# M367 register map
File version: 0.1
CPU: 
Registers are 32-bit, read-write, reset 0x0 unless marked. A register's access mark holds for its fields unless they carry their own. Offsets are from the block's base; [hi:lo] are bit positions; {n}, {i} and the like mark numbered series.

## PG — General Purpose Input_Output Port (PG)
Base 0x400C0600
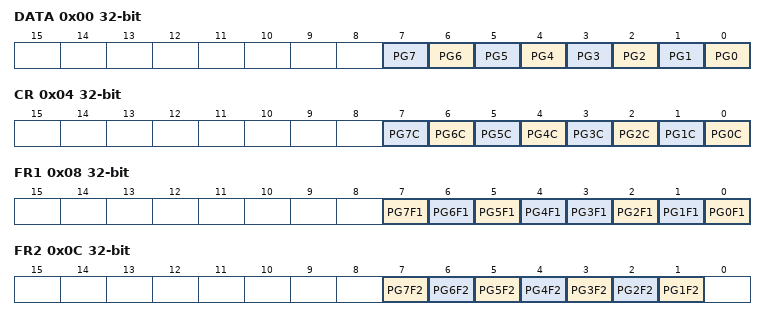
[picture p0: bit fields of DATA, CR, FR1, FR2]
0x00 DATA — PG Data Register
  [n] PG{n} (n=0..7)
0x04 CR — PG Control Register
  [n] PG{n}C (n=0..7)
0x08 FR1 — PG Function Register 1
  [7] PG7F1 ro, [6] PG6F1 ro, [5] PG5F1, [4] PG4F1 ro, [n] PG{n}F1 (n=0..3)
0x0C FR2 — PG Function Register 2
  [n] PG{n}F2 (n=1..7)
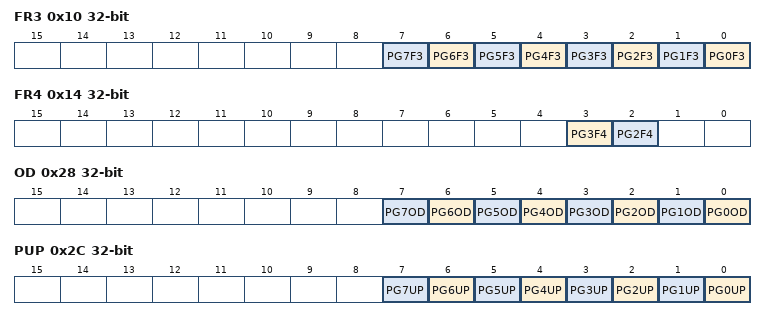
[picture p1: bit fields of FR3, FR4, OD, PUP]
0x10 FR3 — PG Function Register 3
  [n] PG{n}F3 (n=0..7)
0x14 FR4 — PG Function Register 4
  [3] PG3F4, [2] PG2F4
0x28 OD — PG Open Drain Control Register
  [n] PG{n}OD (n=0..7)
0x2C PUP — PG Pull-Up Control Register
  [n] PG{n}UP (n=0..7)
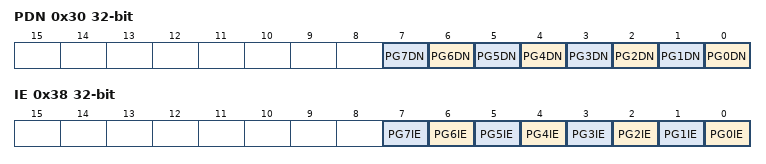
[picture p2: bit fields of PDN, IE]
0x30 PDN — PG Pull-Down Control Register
  [n] PG{n}DN (n=0..7)
0x38 IE — PG Input Enable Control Register
  [n] PG{n}IE (n=0..7)

## PH — General Purpose Input_Output Port (PH)
Base 0x400C0700
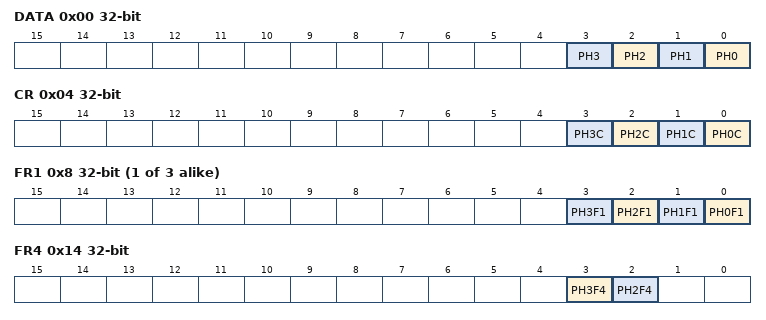
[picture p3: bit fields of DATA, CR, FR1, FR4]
0x00 DATA — PH Data Register
  [n] PH{n} (n=0..3)
0x04 CR — PH Control Register
  [n] PH{n}C (n=0..3)
{0x4+4i} FR{i} (i=1..3) — PH Function Register {i}
  [n] PH{n}F{i} (n=0..3)
0x14 FR4 — PH Function Register 4
  [3] PH3F4, [2] PH2F4
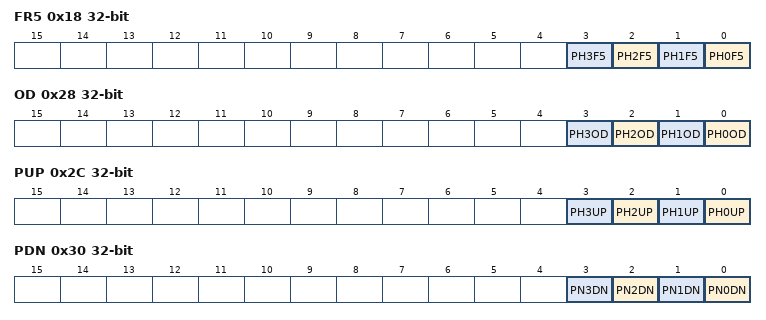
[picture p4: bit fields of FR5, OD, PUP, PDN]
0x18 FR5 — PH Function Register 5
  [n] PH{n}F5 (n=0..3)
0x28 OD — PH Open Drain Control Register
  [n] PH{n}OD (n=0..3)
0x2C PUP — PH Pull-Up Control Register
  [n] PH{n}UP (n=0..3)
0x30 PDN — PH Pull-Down Control Register
  [n] PN{n}DN (n=0..3)
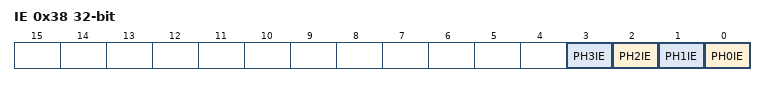
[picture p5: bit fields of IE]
0x38 IE — PH Input Enable Control Register
  [n] PH{n}IE (n=0..3)

## PI — General Purpose Input_Output Port (PI)
Base 0x400C0800
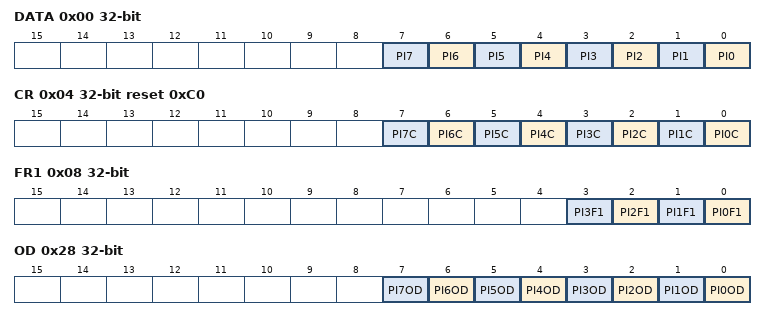
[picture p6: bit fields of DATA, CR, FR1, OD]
0x00 DATA — PI Data Register
  [n] PI{n} (n=0..7)
0x04 CR reset 0xC0 — PI Control Register
  [n] PI{n}C (n=0..7)
0x08 FR1 — PI Function Register 1
  [n] PI{n}F1 (n=0..3)
0x0C FR2 — PI Function Register 2
  [3] PI3F2
0x28 OD — PI Open Drain Control Register
  [n] PI{n}OD (n=0..7)
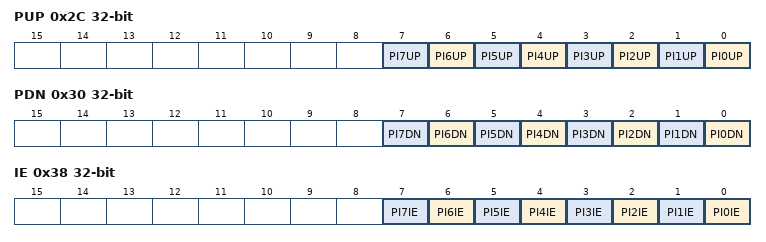
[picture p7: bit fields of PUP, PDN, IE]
0x2C PUP — PI Pull-Up Control Register
  [n] PI{n}UP (n=0..7)
0x30 PDN — PI Pull-Down Control Register
  [n] PI{n}DN (n=0..7)
0x38 IE — PI Input Enable Control Register
  [n] PI{n}IE (n=0..7)

## PK — General Purpose Input_Output Port (PK)
Base 0x400C0A00
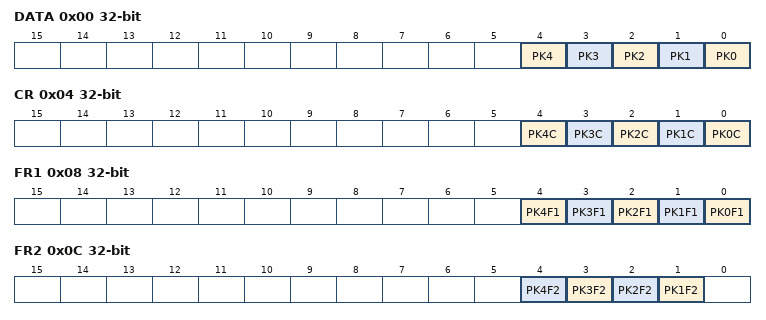
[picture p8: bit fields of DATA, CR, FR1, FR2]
0x00 DATA — PK Data Register
  [n] PK{n} (n=0..4)
0x04 CR — PK Control Register
  [n] PK{n}C (n=0..4)
0x08 FR1 — PK Function Register 1
  [n] PK{n}F1 (n=0..4)
0x0C FR2 — PK Function Register 2
  [n] PK{n}F2 (n=1..4)
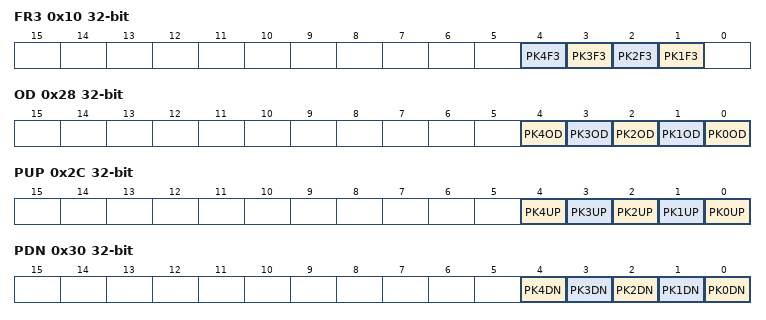
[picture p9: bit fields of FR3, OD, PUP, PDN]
0x10 FR3 — PK Function Register 3
  [n] PK{n}F3 (n=1..4)
0x14 FR4 — PK Function Register 4
  [1] PK1F4
0x28 OD — PK Open Drain Control Register
  [n] PK{n}OD (n=0..4)
0x2C PUP — PK Pull-Up Control Register
  [n] PK{n}UP (n=0..4)
0x30 PDN — PK Pull-Down Control Register
  [n] PK{n}DN (n=0..4)
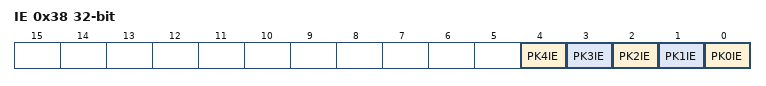
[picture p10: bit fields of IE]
0x38 IE — PK Input Enable Control Register
  [n] PK{n}IE (n=0..4)

## PL — General Purpose Input_Output Port (PL)
Base 0x400C0B00
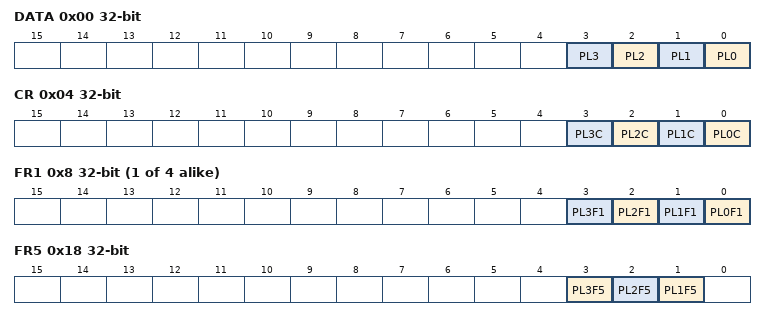
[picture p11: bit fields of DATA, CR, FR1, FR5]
0x00 DATA — PL Data Register
  [n] PL{n} (n=0..3)
0x04 CR — PL Control Register
  [n] PL{n}C (n=0..3)
{0x4+4i} FR{i} (i=1..4) — PL Function Register {i}
  [n] PL{n}F{i} (n=0..3)
0x18 FR5 — PL Function Register 5
  [3] PL3F5, [2] PL2F5, [1] PL1F5
0x1C FR6 — PL Function Register 6
  [3] PL3F6
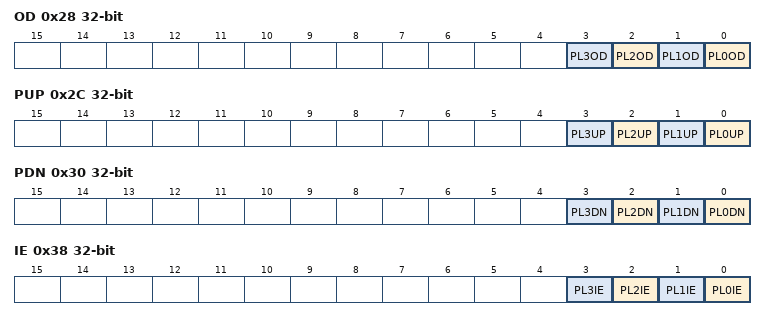
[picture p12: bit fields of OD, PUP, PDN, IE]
0x28 OD — PL Open Drain Control Register
  [n] PL{n}OD (n=0..3)
0x2C PUP — PL Pull-Up Control Register
  [n] PL{n}UP (n=0..3)
0x30 PDN — PL Pull-Down Control Register
  [n] PL{n}DN (n=0..3)
0x38 IE — PL Input Enable Control Register
  [n] PL{n}IE (n=0..3)

## TB0 — 16-bit Timer_Event Counter (TB)
Base 0x400C4000
Same registers: TB1 0x400C4100, TB2 0x400C4200, TB3 0x400C4300, TB4 0x400C4400, TB5 0x400C4500, TB6 0x400C4600, TB7 0x400C4700
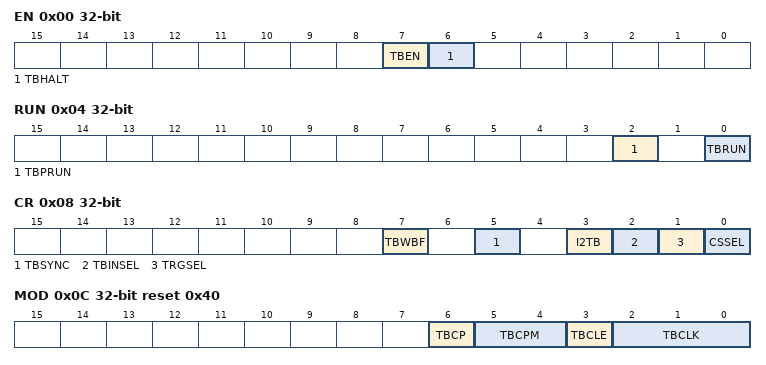
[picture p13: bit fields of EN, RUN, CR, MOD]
0x00 EN — TB Enable Register
  [7] TBEN, [6] TBHALT
0x04 RUN — TB RUN Register
  [2] TBPRUN, [0] TBRUN
0x08 CR — TB Control Register
  [7] TBWBF, [5] TBSYNC, [3] I2TB, [2] TBINSEL, [1] TRGSEL, [0] CSSEL
0x0C MOD reset 0x40 — TB Mode Register
  [6] TBCP wo, [5:4] TBCPM, [3] TBCLE, [2:0] TBCLK
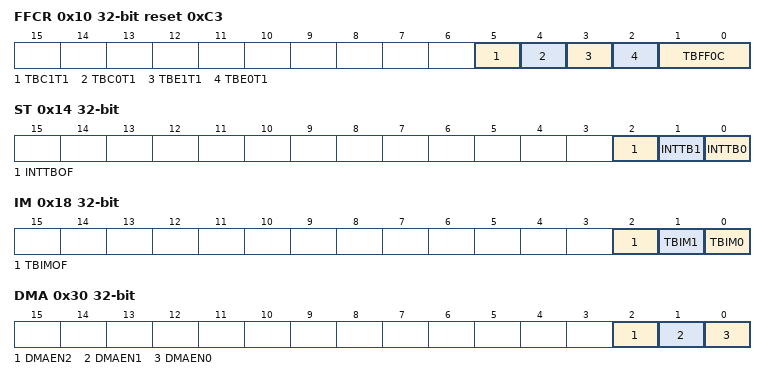
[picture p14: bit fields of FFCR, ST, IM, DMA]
0x10 FFCR reset 0xC3 — TB Flip-Flop Control Register
  [5] TBC1T1, [4] TBC0T1, [3] TBE1T1, [2] TBE0T1, [1:0] TBFF0C
0x14 ST ro — TB Status Register
  [2] INTTBOF, [1] INTTB1, [0] INTTB0
0x18 IM — TB Interrupt Mask Register
  [2] TBIMOF, [1] TBIM1, [0] TBIM0
0x1C UC ro — TB Read Capture Register
  [15:0] TBUC
0x20 RG0 — TB RG0 Timer Register
  [15:0] TBRG0
0x24 RG1 — TB RG1 Timer Register
  [15:0] TBRG1
0x28 CP0 ro (reset mask 0xFFFF0000) — TB CP0 Capture Register
  [15:0] TBCP0
0x2C CP1 ro (reset mask 0xFFFF0000) — TB CP1 Capture Register
  [15:0] TBCP1
0x30 DMA (reset mask 0xFFFFFFF8) — TB DMA Enable Register
  [2] DMAEN2, [1] DMAEN1, [0] DMAEN0
